VERSION ""

NS_ :

BS_:

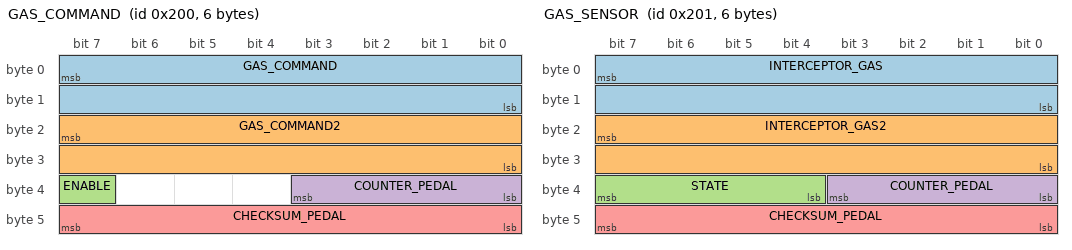
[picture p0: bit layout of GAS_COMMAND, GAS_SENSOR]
BO_ 512 GAS_COMMAND: 6 NEO
 SG_ GAS_COMMAND : 7|16@0+ (0.125677,-75.909) [0|1] "" INTERCEPTOR
 SG_ GAS_COMMAND2 : 23|16@0+ (0.251976,-76.601) [0|1] "" INTERCEPTOR
 SG_ ENABLE : 39|1@0+ (1,0) [0|1] "" INTERCEPTOR
 SG_ COUNTER_PEDAL : 35|4@0+ (1,0) [0|15] "" INTERCEPTOR
 SG_ CHECKSUM_PEDAL : 47|8@0+ (1,0) [0|255] "" INTERCEPTOR

BO_ 513 GAS_SENSOR: 6 INTERCEPTOR
 SG_ INTERCEPTOR_GAS : 7|16@0+ (0.125677,-75.909) [0|1] "" NEO
 SG_ INTERCEPTOR_GAS2 : 23|16@0+ (0.251976,-76.601) [0|1] "" NEO
 SG_ STATE : 39|4@0+ (1,0) [0|15] "" NEO
 SG_ COUNTER_PEDAL : 35|4@0+ (1,0) [0|15] "" NEO
 SG_ CHECKSUM_PEDAL : 47|8@0+ (1,0) [0|255] "" NEO

BO_ 189 EBCMRegenPaddle: 7 K17_EBCM
 SG_ RegenPaddle : 7|4@0+ (1,0) [0|0] ""  NEO

BO_ 190 ECMAcceleratorPos: 6 K20_ECM
 SG_ BrakePedalPos : 15|8@0+ (1,0) [0|0] "sticky"  NEO
 SG_ GasPedalAndAcc : 23|8@0+ (1,0) [0|0] ""  NEO

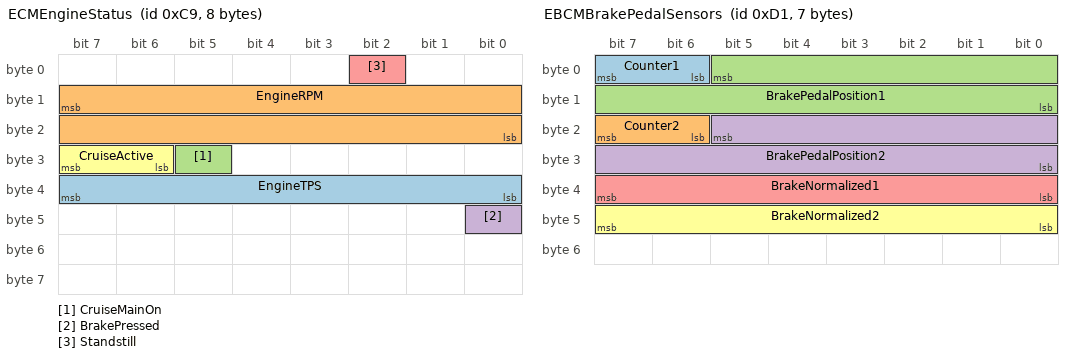
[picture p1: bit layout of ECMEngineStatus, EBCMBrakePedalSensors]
BO_ 201 ECMEngineStatus: 8 K20_ECM
 SG_ EngineTPS : 39|8@0+ (0.392156863,0) [0|100.000000065] "%" NEO
 SG_ EngineRPM : 15|16@0+ (0.25,0) [0|0] "RPM" NEO
 SG_ CruiseMainOn : 29|1@0+ (1,0) [0|1] "" NEO
 SG_ BrakePressed : 40|1@0+ (1,0) [0|1] "" NEO
 SG_ Standstill : 2|1@0+ (1,0) [0|1] "" NEO
 SG_ CruiseActive : 31|2@0+ (1,0) [0|3] "" NEO

BO_ 209 EBCMBrakePedalSensors: 7 K17_EBCM
 SG_ Counter1 : 7|2@0+ (1,0) [0|3] "" XXX
 SG_ Counter2 : 23|2@0+ (1,0) [0|3] "" XXX
 SG_ BrakePedalPosition1 : 5|14@0+ (1,0) [0|16383] "" XXX
 SG_ BrakePedalPosition2 : 21|14@0- (-1,0) [0|16383] "" XXX
 SG_ BrakeNormalized1 : 39|8@0+ (1,0) [0|255] "" XXX
 SG_ BrakeNormalized2 : 47|8@0- (-1,0) [0|255] "" XXX

BO_ 241 EBCMBrakePedalPosition: 6 K17_EBCM
 SG_ BrakePressed : 1|1@0+ (1,0) [0|1] "" XXX
 SG_ BrakePedalPosition : 15|8@0+ (1,0) [0|255] ""  NEO

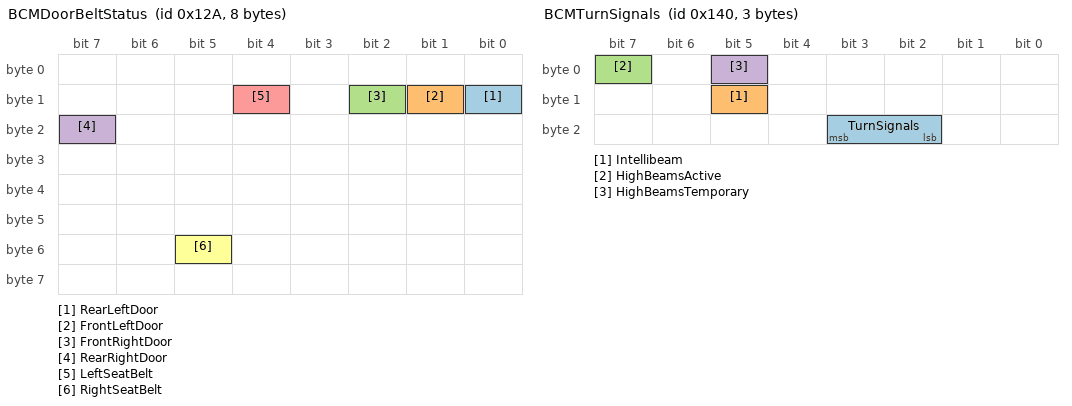
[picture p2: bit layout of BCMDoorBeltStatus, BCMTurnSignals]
BO_ 298 BCMDoorBeltStatus: 8 K9_BCM
 SG_ RearLeftDoor : 8|1@0+ (1,0) [0|0] ""  NEO
 SG_ FrontLeftDoor : 9|1@0+ (1,0) [0|0] ""  NEO
 SG_ FrontRightDoor : 10|1@0+ (1,0) [0|0] ""  NEO
 SG_ RearRightDoor : 23|1@0+ (1,0) [0|0] ""  NEO
 SG_ LeftSeatBelt : 12|1@0+ (1,0) [0|0] ""  NEO
 SG_ RightSeatBelt : 53|1@0+ (1,0) [0|0] ""  NEO

BO_ 309 ECMPRDNL: 8 K20_ECM
 SG_ PRNDL : 2|3@0+ (1,0) [0|0] ""  NEO
 SG_ ESPButton : 4|1@0+ (1,0) [0|1] "" XXX

BO_ 320 BCMTurnSignals: 3 K9_BCM
 SG_ TurnSignals : 19|2@0+ (1,0) [0|0] ""  NEO
 SG_ Intellibeam : 13|1@0+ (1,0) [0|1] "" XXX
 SG_ HighBeamsActive : 7|1@0+ (1,0) [0|1] "" XXX
 SG_ HighBeamsTemporary : 5|1@0+ (1,0) [0|1] "" XXX

BO_ 328 PSCM_148: 1 K43_PSCM

BO_ 381 ESPStatus: 6 K20_ECM
 SG_ TractionControlOn : 5|1@0+ (1,0) [0|0] ""  NEO
 SG_ MSG17D_AccPower : 35|12@0- (1,0) [0|0] ""  NEO

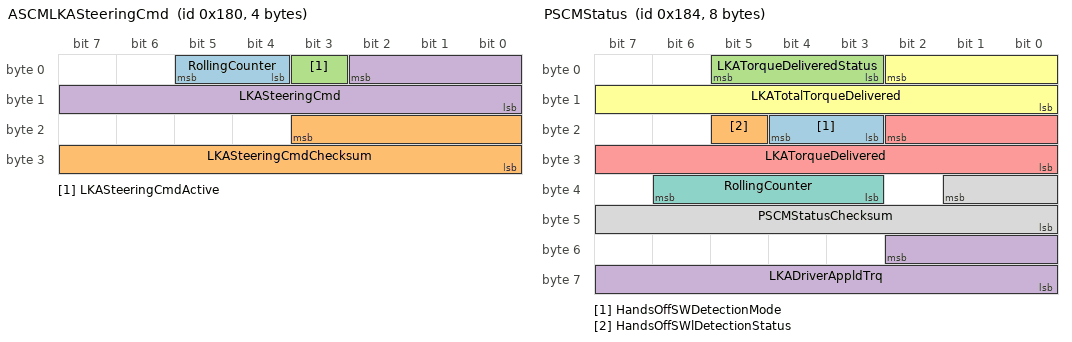
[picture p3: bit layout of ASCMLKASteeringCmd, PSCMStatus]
BO_ 384 ASCMLKASteeringCmd: 4 NEO
 SG_ RollingCounter : 5|2@0+ (1,0) [0|0] ""  NEO
 SG_ LKASteeringCmdChecksum : 19|12@0+ (1,0) [0|0] ""  NEO
 SG_ LKASteeringCmdActive : 3|1@0+ (1,0) [0|0] ""  NEO
 SG_ LKASteeringCmd : 2|11@0- (1,0) [0|0] ""  NEO

BO_ 388 PSCMStatus: 8 K43_PSCM
 SG_ HandsOffSWDetectionMode : 20|2@0+ (1,0) [0|3] "" NEO
 SG_ HandsOffSWlDetectionStatus : 21|1@0+ (1,0) [0|1] "" NEO
 SG_ LKATorqueDeliveredStatus : 5|3@0+ (1,0) [0|7] "" NEO
 SG_ LKADriverAppldTrq : 50|11@0- (0.01,0) [-10.24|10.23] "Nm" NEO
 SG_ LKATorqueDelivered : 18|11@0- (0.01,0) [0|1] "" NEO
 SG_ LKATotalTorqueDelivered : 2|11@0- (0.01,0) [-10.24|10.23] "Nm" NEO
 SG_ RollingCounter : 38|4@0+ (1,0) [0|15] "" XXX
 SG_ PSCMStatusChecksum : 33|10@0+ (1,0) [0|1023] "" XXX

BO_ 417 AcceleratorPedal: 7 XXX
 SG_ AcceleratorPedal : 55|8@0+ (1,0) [0|0] ""  NEO

BO_ 451 GasAndAcc: 8 XXX
 SG_ GasPedalAndAcc2 : 55|8@0+ (1,0) [0|0] ""  NEO

BO_ 452 AcceleratorPedal2: 8 XXX
 SG_ CruiseState : 15|3@0+ (1,0) [0|7] ""  NEO
 SG_ AcceleratorPedal2 : 47|8@0+ (1,0) [0|0] ""  NEO

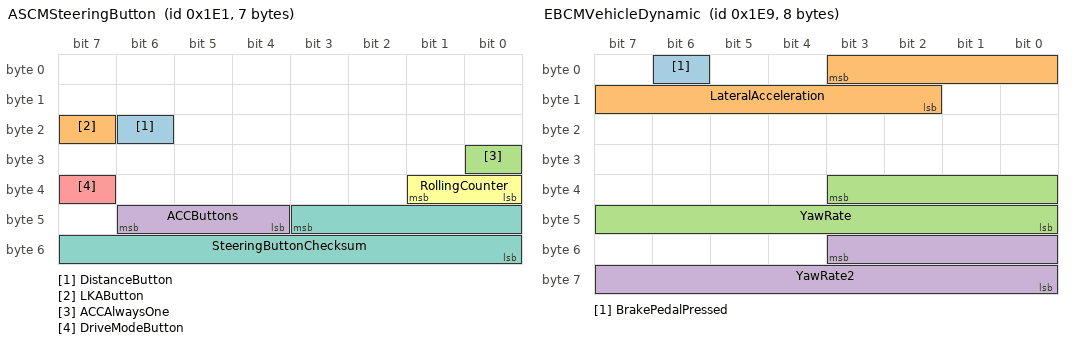
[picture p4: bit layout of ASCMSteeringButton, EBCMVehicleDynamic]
BO_ 481 ASCMSteeringButton: 7 K124_ASCM
 SG_ DistanceButton : 22|1@0+ (1,0) [0|0] ""  NEO
 SG_ LKAButton : 23|1@0+ (1,0) [0|0] ""  NEO
 SG_ ACCAlwaysOne : 24|1@0+ (1,0) [0|1] "" XXX
 SG_ ACCButtons : 46|3@0+ (1,0) [0|0] ""  NEO
 SG_ DriveModeButton : 39|1@0+ (1,0) [0|1] "" XXX
 SG_ RollingCounter : 33|2@0+ (1,0) [0|3] "" NEO
 SG_ SteeringButtonChecksum : 43|12@0+ (1,0) [0|255] "" NEO

BO_ 485 PSCMSteeringAngle: 8 K43_PSCM
 SG_ SteeringWheelAngle : 15|16@0- (0.0625,0) [-2047|2047] "deg"  NEO
 SG_ SteeringWheelRate : 27|12@0- (1,0) [-2047|2047] "deg/s"  NEO

BO_ 489 EBCMVehicleDynamic: 8 K17_EBCM
 SG_ BrakePedalPressed : 6|1@0+ (1,0) [0|0] "" NEO
 SG_ LateralAcceleration : 3|10@0- (0.161,0) [-2047|2047] "m/s2" NEO
 SG_ YawRate : 35|12@0- (0.625,0) [0|1] "" NEO
 SG_ YawRate2 : 51|12@0- (0.0625,0) [-2047|2047] "grad/s" NEO

BO_ 352 BCMImmobilizer: 5 K9_BCM
 SG_ ImmobilizerInfo : 7|32@0+ (1,0) [0|4294967295] "" XXX

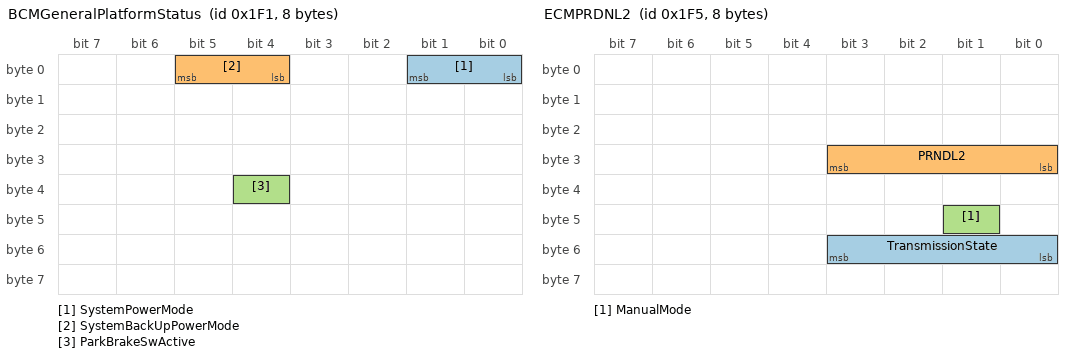
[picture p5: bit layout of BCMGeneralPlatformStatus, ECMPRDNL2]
BO_ 497 BCMGeneralPlatformStatus: 8 K9_BCM
 SG_ SystemPowerMode : 1|2@0+ (1,0) [0|3] "" XXX
 SG_ SystemBackUpPowerMode : 5|2@0+ (1,0) [0|3] "" XXX
 SG_ ParkBrakeSwActive : 36|1@0+ (1,0) [0|3] "" XXX

BO_ 501 ECMPRDNL2: 8 K20_ECM
 SG_ TransmissionState : 48|4@1+ (1,0) [0|7] "" NEO
 SG_ PRNDL2 : 27|4@0+ (1,0) [0|255] "" NEO
 SG_ ManualMode : 41|1@0+ (1,0) [0|1] "" NEO

BO_ 532 BRAKE_RELATED: 6 XXX
 SG_ UserBrakePressure : 0|9@0+ (1,0) [0|511] "" XXX

BO_ 560 EPBStatus: 8 EPB
 SG_ EPBClosed : 12|1@0+ (1,0) [0|1] ""  NEO

BO_ 562 EBCMFrictionBrakeStatus: 8 K17_EBCM
 SG_ FrictionBrakeUnavailable : 46|1@0+ (1,0) [0|1] "" XXX

BO_ 608 SPEED_RELATED: 8 XXX
 SG_ RollingCounter : 5|2@0+ (1,0) [0|0] "" XXX
 SG_ ClusterSpeed : 31|8@0+ (1,0) [0|0] "" XXX

BO_ 711 BECMBatteryVoltageCurrent: 6 K17_EBCM
 SG_ HVBatteryVoltage : 31|12@0+ (0.125,0) [0|511.875] "V"  NEO
 SG_ HVBatteryCurrent : 12|13@0- (0.15,0) [-614.4|614.25] "A"  NEO

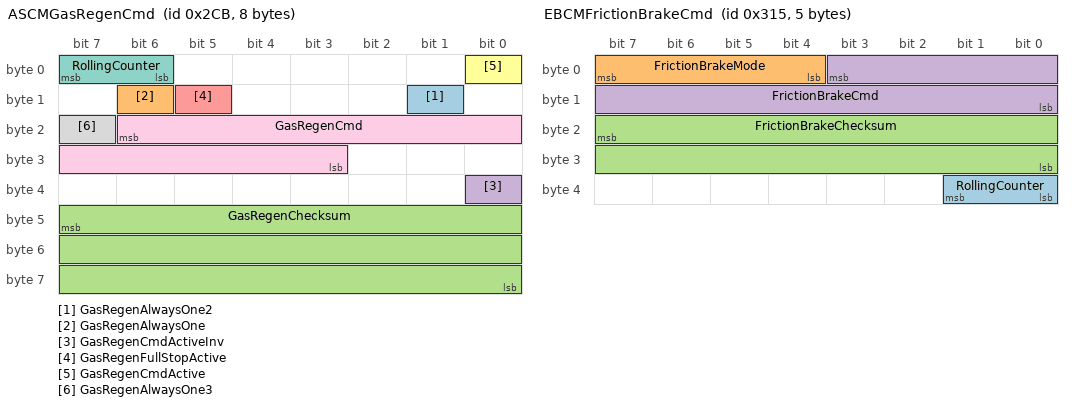
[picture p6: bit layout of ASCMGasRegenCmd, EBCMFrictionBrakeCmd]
BO_ 715 ASCMGasRegenCmd: 8 K124_ASCM
 SG_ GasRegenAlwaysOne2 : 9|1@0+ (1,0) [0|1] ""  NEO
 SG_ GasRegenAlwaysOne : 14|1@0+ (1,0) [0|1] ""  NEO
 SG_ GasRegenChecksum : 47|24@0+ (1,0) [0|0] ""  NEO
 SG_ GasRegenCmdActiveInv : 32|1@0+ (1,0) [0|0] ""  NEO
 SG_ GasRegenFullStopActive : 13|1@0+ (1,0) [0|0] ""  NEO
 SG_ GasRegenCmdActive : 0|1@0+ (1,0) [0|0] ""  NEO
 SG_ RollingCounter : 7|2@0+ (1,0) [0|0] ""  NEO
 SG_ GasRegenAlwaysOne3 : 23|1@0+ (1,0) [0|1] ""  NEO
 SG_ GasRegenCmd : 22|12@0+ (1,0) [0|0] ""  NEO

BO_ 717 ASCM_2CD: 5 K124_ASCM

BO_ 761 BRAKE_RELATED_2: 7 XXX
 SG_ UserBrakePressure2 : 47|9@0+ (1,0) [0|511] "" XXX

BO_ 789 EBCMFrictionBrakeCmd: 5 K124_ASCM
 SG_ RollingCounter : 33|2@0+ (1,0) [0|0] ""  NEO
 SG_ FrictionBrakeMode : 7|4@0+ (1,0) [0|0] ""  NEO
 SG_ FrictionBrakeChecksum : 23|16@0+ (1,0) [0|0] ""  NEO
 SG_ FrictionBrakeCmd : 3|12@0- (1,0) [0|0] ""  NEO

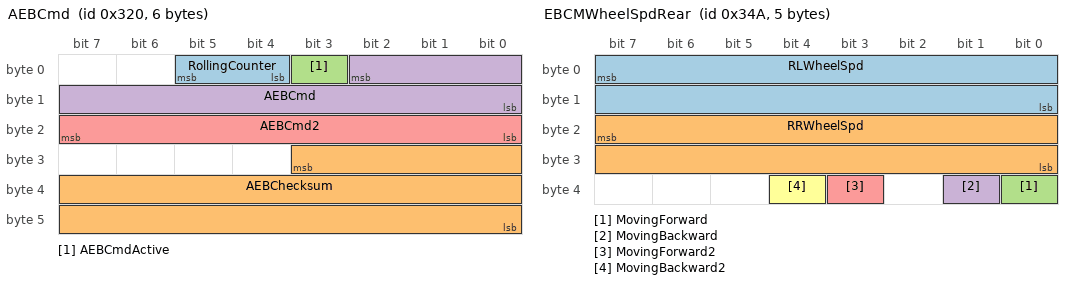
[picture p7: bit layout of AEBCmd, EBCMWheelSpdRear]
BO_ 800 AEBCmd: 6 K124_ASCM
 SG_ RollingCounter : 5|2@0+ (1,0) [0|3] "" NEO
 SG_ AEBChecksum : 27|20@0+ (1,0) [0|0] "" NEO
 SG_ AEBCmdActive : 3|1@1+ (1,0) [0|1] "" NEO
 SG_ AEBCmd : 2|11@0+ (1,0) [0|0] "" NEO
 SG_ AEBCmd2 : 23|8@0+ (1,0) [0|0] "" NEO

BO_ 810 TCICOnStarGPSPosition: 8 K73_TCIC
 SG_ GPSLongitude : 39|32@0+ (1,-2147483648) [0|0] "milliarcsecond"  NEO
 SG_ GPSLatitude : 7|32@0+ (1,0) [0|0] "milliarcsecond"  NEO

BO_ 840 EBCMWheelSpdFront: 5 K17_EBCM
 SG_ FLWheelSpd : 7|16@0+ (0.0311,0) [0|255] "km/h"  NEO
 SG_ FRWheelSpd : 23|16@0+ (0.0311,0) [0|255] "km/h"  NEO

BO_ 842 EBCMWheelSpdRear: 5 K17_EBCM
 SG_ RLWheelSpd : 7|16@0+ (0.0311,0) [0|255] "km/h"  NEO
 SG_ RRWheelSpd : 23|16@0+ (0.0311,0) [0|255] "km/h"  NEO
 SG_ MovingForward : 32|1@0+ (1,0) [0|1] "" XXX
 SG_ MovingBackward : 33|1@0+ (1,0) [0|1] "" XXX
 SG_ MovingForward2 : 35|1@1+ (1,0) [0|1] "" XXX
 SG_ MovingBackward2 : 36|1@0+ (1,0) [0|1] "" XXX

BO_ 869 ASCM_365: 4 K124_ASCM

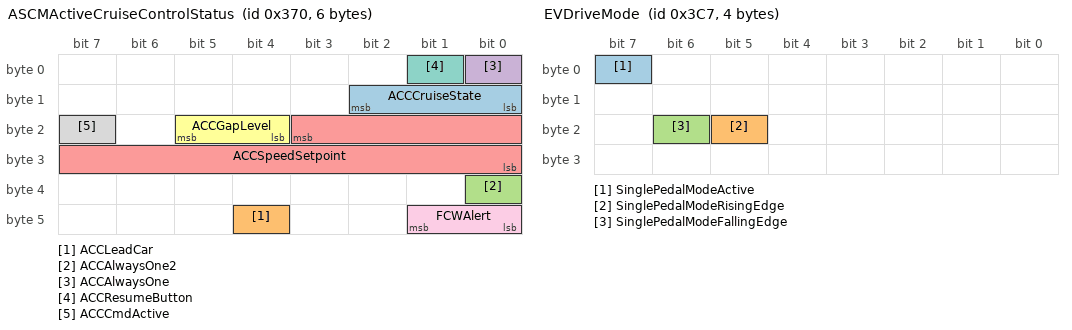
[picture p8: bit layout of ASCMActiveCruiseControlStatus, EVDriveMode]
BO_ 880 ASCMActiveCruiseControlStatus: 6 K124_ASCM
 SG_ ACCCruiseState : 8|3@1+ (1,0) [0|7] "" XXX
 SG_ ACCLeadCar : 44|1@0+ (1,0) [0|0] "" Vector__XXX
 SG_ ACCAlwaysOne2 : 32|1@0+ (1,0) [0|0] "" Vector__XXX
 SG_ ACCAlwaysOne : 0|1@0+ (1,0) [0|0] "" Vector__XXX
 SG_ ACCSpeedSetpoint : 19|12@0+ (0.0625,0) [0|255.9375] "km/h"  NEO
 SG_ ACCGapLevel : 21|2@0+ (1,0) [0|0] ""  NEO
 SG_ ACCResumeButton : 1|1@0+ (1,0) [0|0] ""  NEO
 SG_ ACCCmdActive : 23|1@0+ (1,0) [0|0] ""  NEO
 SG_ FCWAlert : 41|2@0+ (1,0) [0|3] "" XXX

BO_ 967 EVDriveMode: 4 XXX
 SG_ SinglePedalModeActive : 7|1@0+ (1,0) [0|1] "" XXX
 SG_ SinglePedalModeRisingEdge : 21|1@0+ (1,0) [0|1] "" XXX
 SG_ SinglePedalModeFallingEdge : 22|1@0+ (1,0) [0|1] "" XXX

BO_ 977 ECMCruiseControl: 8 K20_ECM
 SG_ CruiseActive : 39|1@0+ (1,0) [0|3] "" NEO
 SG_ CruiseSetSpeed : 19|12@0+ (0.0625,0) [0|0] "km/h" NEO

BO_ 1001 ECMVehicleSpeed: 8 K20_ECM
 SG_ VehicleSpeed : 7|16@0+ (0.01,0) [0|0] "mph"  NEO
 SG_ VehicleSpeedLeft : 39|16@0+ (0.01,0) [0|0] "mph" NEO

BO_ 1033 ASCMKeepAlive: 7 NEO
 SG_ ASCMKeepAliveAllZero : 7|56@0+ (1,0) [0|0] ""  NEO

BO_ 1034 ASCM_40A: 7 K124_ASCM

BO_ 1217 ECMEngineCoolantTemp: 8 K20_ECM
 SG_ EngineCoolantTemp : 23|8@0+ (1,-40) [0|0] "C"  NEO

BO_ 1249 VIN_Part2: 8 K20_ECM
 SG_ VINPart2 : 7|64@0+ (1,0) [0|0] ""  NEO

BO_ 1296 ASCM_510: 4 K124_ASCM

BO_ 1300 VIN_Part1: 8 K20_ECM
 SG_ VINPart1 : 7|64@0+ (1,0) [0|0] ""  NEO

BO_ 1912 PSCM_778: 8 K43_PSCM

BO_ 1930 ASCM_78A: 7 K124_ASCM

BO_TX_BU_ 384 : K124_ASCM,NEO;
BO_TX_BU_ 880 : NEO,K124_ASCM;
BO_TX_BU_ 1033 : K124_ASCM,NEO;
BO_TX_BU_ 715 : NEO,K124_ASCM;
BO_TX_BU_ 789 : NEO,K124_ASCM;
BO_TX_BU_ 800 : NEO,K124_ASCM;

BU_: ABS ESP ECU TCU SAS

CM_ BU_ K16_BECM "Battery Energy Control Module";
CM_ BU_ K73_TCIC "Telematics Communication Control Module";
CM_ BU_ K9_BCM "Body Control Module";
CM_ BU_ K43_PSCM "Power Steering Control Module";
CM_ BU_ K17_EBCM "Electronic Brake Control Module";
CM_ BU_ K20_ECM "Engine Control Module";
CM_ BU_ K114B_HPCM "Hybrid Powertrain Control Module";
CM_ BU_ NEO "Comma NEO";
CM_ BU_ K124_ASCM "Active Safety Control Module";
CM_ SG_ 381 MSG17D_AccPower "Need to investigate";
CM_ SG_ 190 GasPedalAndAcc "ACC baseline is 62";
CM_ SG_ 451 GasPedalAndAcc2 "ACC baseline is 62";
CM_ SG_ 715 RollingCounter2 "Values cycle between 0, 7, 10, 13";
BA_DEF_  "UseGMParameterIDs" INT 0 0;
BA_DEF_  "ProtocolType" STRING ;
BA_DEF_  "BusType" STRING ;
BA_DEF_DEF_  "UseGMParameterIDs" 1;
BA_DEF_DEF_  "ProtocolType" "GMLAN";
BA_DEF_DEF_  "BusType" "";
BA_ "BusType" "CAN";
BA_ "UseGMParameterIDs" 0;
VAL_ 513 STATE 5 "FAULT_TIMEOUT" 4 "FAULT_STARTUP" 3 "FAULT_SCE" 2 "FAULT_SEND" 1 "FAULT_BAD_CHECKSUM" 0 "NO_FAULT" ;

VAL_ 780 CRUISE_SPEED 255 "no_speed" 252 "stopped";
VAL_ 780 HUD_LEAD 3 "acc_off" 2 "solid_car" 1 "dashed_car" 0 "no_car";
VAL_ 884 DASHBOARD_ALERT 0 "none" 51 "acc_problem" 55 "cmbs_problem" 75 "key_not_detected" 79 "fasten_seatbelt" 111 "lkas_problem" 131 "brake_system_problem" 132 "brake_hold_problem" 139 "tbd" 161 "door_open";
VAL_ 891 WIPERS 4 "High" 2 "Low" 0 "Off";

VAL_ 399 STEER_STATUS 6 "tmp_fault" 5 "fault_1" 4 "no_torque_alert_2" 3 "low_speed_lockout" 2 "no_torque_alert_1" 0 "normal";

VAL_ 401 GEAR_SHIFTER 32 "L" 16 "S" 8 "D" 4 "N" 2 "R" 1 "P";
VAL_ 401 GEAR 7 "L" 10 "S" 4 "D" 3 "N" 2 "R" 1 "P";
